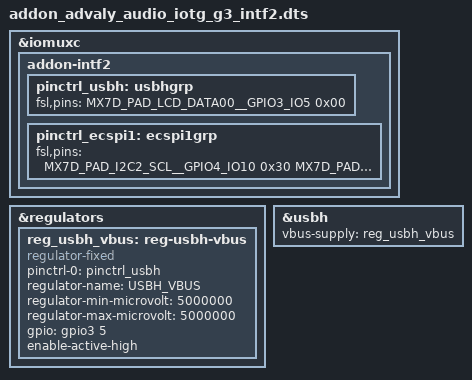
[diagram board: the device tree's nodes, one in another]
// SPDX-License-Identifier: GPL-2.0
/*
 * Copyright (C) 2024 ADVALY SYSTEM Inc. All Rights Reserved.
 */

#include "../../../../arch/arm/boot/dts/imx7d-pinfunc.h"

/dts-v1/;
/plugin/;
/ {
	fragment@0 {
		target = <&iomuxc>;
		__overlay__ {
			addon-intf2 {
				pinctrl_usbh: usbhgrp {
					fsl,pins = <
						MX7D_PAD_LCD_DATA00__GPIO3_IO5 0x00	/* GPIO_AOM2_VBUS_PWREN */
					>;
				};

				pinctrl_ecspi1: ecspi1grp {
					fsl,pins = <
						MX7D_PAD_I2C2_SCL__GPIO4_IO10		0x30	/* INTF2_24 */
						MX7D_PAD_I2C2_SDA__GPIO4_IO11		0x30	/* INTF2_25 */
						MX7D_PAD_SAI2_TX_BCLK__GPIO6_IO20	0x30	/* INTF2_47 */
						MX7D_PAD_SAI2_RX_DATA__GPIO6_IO21	0x30	/* INTF2_48 */
						MX7D_PAD_SAI2_TX_DATA__GPIO6_IO22	0x30	/* INTF2_49 */
					>;
				};
			};
		};
	};

	fragment@1 {
		target = <&regulators>;
		__overlay__ {
			reg_usbh_vbus: reg-usbh-vbus {
				compatible = "regulator-fixed";
				pinctrl-names = "default";
				pinctrl-0 = <&pinctrl_usbh>;
				regulator-name = "USBH_VBUS";
				regulator-min-microvolt = <5000000>;
				regulator-max-microvolt = <5000000>;
				gpio = <&gpio3 5 0>;
				enable-active-high;
			};
		};
	};

	fragment@2 {
		target = <&usbh>;
		__overlay__ {
			vbus-supply = <&reg_usbh_vbus>;
		};
	};

};
